# CY8C5888LTI_LP097 register map
File version: 0.1
CY8C58LP
Registers are 8-bit, read-write, no defined reset value unless marked. A register's access mark holds for its fields unless they carry their own. Offsets are from the block's base; lines under a group give offsets from that group; [hi:lo] are bit positions; {n}, {i} and the like mark numbered series; 'fields as' and 'values as' point back to an identical list; <NAME> marks a mode.

## Memory map
0x00000000 PWM_PERISTALTISK_1
0x00000000 PWM_PERISTALTISK_2
0x00000000 DS18x8_TimerDelay
0x00000000 DS18x8_ControlReg_SEL
0x00000000 DS18x8_ControlReg_DRV
0x00000000 DS18x8_StatusReg_BUS
0x00000000 DS18x8_Trigger
0x00000000 ADC_PH — SAR ADC

## PWM_PERISTALTISK_1
Base 0x00000000
0x4000642D PWM_PERISTALTISK_1__COMPARE1 — UDB.D0 - Assigned Compare1 Value
0x4000643D PWM_PERISTALTISK_1__COMPARE2 — UDB.D1 - Assigned Compare2 Value
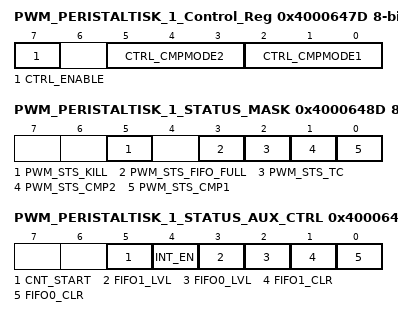
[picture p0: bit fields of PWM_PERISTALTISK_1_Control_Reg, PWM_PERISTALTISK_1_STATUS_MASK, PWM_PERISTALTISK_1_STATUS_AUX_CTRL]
0x4000647D PWM_PERISTALTISK_1_Control_Reg — UDB Control Register - Assigned Control Register Value
  [7] CTRL_ENABLE — Enable the PWM
  [5:3] CTRL_CMPMODE2 — Compare mode 2
  [2:0] CTRL_CMPMODE1 — Compare mode 1
0x4000648D PWM_PERISTALTISK_1_STATUS_MASK — UDB Status bits Interrupt Mask Enable Register
  [5] PWM_STS_KILL ro — Enables the Interrupt on Kill
  [3] PWM_STS_FIFO_FULL ro — FIFO Full Status Mask
  [2] PWM_STS_TC ro — Enables the Interrupt on Terminal Count
  [1] PWM_STS_CMP2 ro — Enables the Interrupt on Compare 2
  [0] PWM_STS_CMP1 ro — Enables the Interrupt on Compare 1
0x4000649D PWM_PERISTALTISK_1_STATUS_AUX_CTRL — UDB Auxilliary Control Register
  [5] CNT_START — FIFO0 clear
    0=E_CNT_START0 (Disable counter); 1=E_CNT_START1 (Enable counter)
  [4] INT_EN
    0=E_INT_EN0 (Interrupt disabled); 1=E_INT_EN1 (Interrupt enabled)
  [3] FIFO1_LVL — FIFO level
    0=E_FIFO_LVL_0 (FIFO LVL: input mode: FIFO not full; output mode: FIFO not empty); 1=E_FIFO_LVL_1 (FIFO LVL: input mode: FIFO at least 1/2 empty; output mode: FIFO at least 1/2 full)
  [2] FIFO0_LVL — FIFO level
    values as FIFO1_LVL
  [1] FIFO1_CLR — FIFO1 clear
    0=E_FIFO_CLR_0 (Normal FIFO operation); 1=E_FIFO_CLR_1 (Clear FIFO state)
  [0] FIFO0_CLR — FIFO0 clear
    values as FIFO1_CLR

## PWM_PERISTALTISK_2
Base 0x00000000
0x40006421 PWM_PERISTALTISK_2_COMPARE_Reg_ — UDB.D0 - Assigned Compare Value
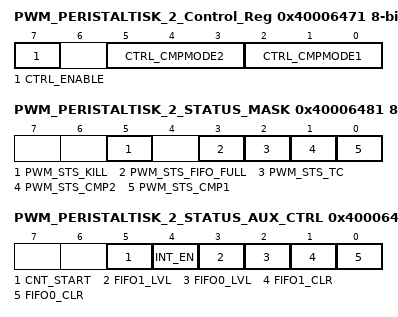
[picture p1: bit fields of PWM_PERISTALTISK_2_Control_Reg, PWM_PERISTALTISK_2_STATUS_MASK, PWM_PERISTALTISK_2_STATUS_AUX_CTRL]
0x40006471 PWM_PERISTALTISK_2_Control_Reg — UDB Control Register - Assigned Control Register Value
  [7] CTRL_ENABLE — Enable the PWM
  [5:3] CTRL_CMPMODE2 — Compare mode 2
  [2:0] CTRL_CMPMODE1 — Compare mode 1
0x40006481 PWM_PERISTALTISK_2_STATUS_MASK — UDB Status bits Interrupt Mask Enable Register
  fields as PWM_PERISTALTISK_1.PWM_PERISTALTISK_1_STATUS_MASK
0x40006491 PWM_PERISTALTISK_2_STATUS_AUX_CTRL — UDB Auxilliary Control Register
  fields as PWM_PERISTALTISK_1.PWM_PERISTALTISK_1_STATUS_AUX_CTRL

## DS18x8_TimerDelay
Base 0x00000000
0x40006402 DS18x8_TimerDelay_COUNTER 16-bit — UDB.A0 - Current Down Counter Value
0x40006422 DS18x8_TimerDelay_PERIOD 16-bit — UDB.D0 - Assigned Period
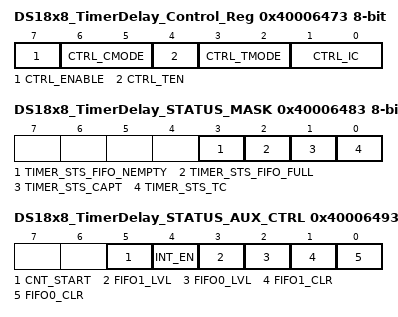
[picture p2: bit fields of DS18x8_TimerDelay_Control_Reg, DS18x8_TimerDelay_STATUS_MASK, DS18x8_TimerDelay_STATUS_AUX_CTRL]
0x40006473 DS18x8_TimerDelay_Control_Reg — UDB Control Register - Assigned Control Register Value
  [7] CTRL_ENABLE — Enable the Timer
  [6:5] CTRL_CMODE — Capture Mode
  [4] CTRL_TEN — Trigger Enable Bit
  [3:2] CTRL_TMODE — Trigger Mode
  [1:0] CTRL_IC — Interrupt Count
0x40006483 DS18x8_TimerDelay_STATUS_MASK — UDB Status bits Interrupt Mask Enable Register
  [3] TIMER_STS_FIFO_NEMPTY ro — FIFO Empty status
  [2] TIMER_STS_FIFO_FULL ro — FIFO Full Status
  [1] TIMER_STS_CAPT ro — Enables the Interrupt on Capture
  [0] TIMER_STS_TC ro — Enables the Interrupt on TC
0x40006493 DS18x8_TimerDelay_STATUS_AUX_CTRL — UDB Auxilliary Control Register
  fields as PWM_PERISTALTISK_1.PWM_PERISTALTISK_1_STATUS_AUX_CTRL

## DS18x8_ControlReg_SEL
Base 0x00000000
0x4000647C DS18x8_ControlReg_SEL_CONTROL_REG

## DS18x8_ControlReg_DRV
Base 0x00000000
0x40006472 DS18x8_ControlReg_DRV_CONTROL_REG

## DS18x8_StatusReg_BUS
Base 0x00000000
0x40006462 DS18x8_StatusReg_BUS_STATUS_REG
0x40006482 DS18x8_StatusReg_BUS_MASK_REG
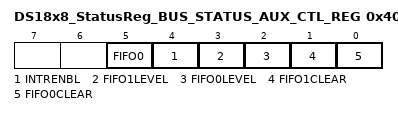
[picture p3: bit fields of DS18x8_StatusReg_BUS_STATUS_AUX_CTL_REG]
0x40006492 DS18x8_StatusReg_BUS_STATUS_AUX_CTL_REG
  [5] FIFO0 — FIFO0 clear
    1=ENABLED (Enable counter); 0=DISABLED (Disable counter)
  [4] INTRENBL — Enables or disables the Interrupt
    1=ENABLED (Interrupt enabled); 0=DISABLED (Interrupt disabled)
  [3] FIFO1LEVEL — FIFO level
    1=ENABLED (FIFO LVL: input mode: FIFO at least 1/2 empty; output mode: FIFO at least 1/2 full); 0=DISABLED (FIFO LVL: input mode: FIFO not full; output mode: FIFO not empty)
  [2] FIFO0LEVEL — FIFO level
    values as FIFO1LEVEL
  [1] FIFO1CLEAR — FIFO clear
    1=ENABLED (Clear FIFO state); 0=DISABLED (Normal FIFO operation)
  [0] FIFO0CLEAR — FIFO clear
    values as FIFO1CLEAR

## DS18x8_Trigger
Base 0x00000000
0x40006470 DS18x8_Trigger_CONTROL_REG

## ADC_PH — SAR ADC
Base 0x00000000
0x40004614 SAR_TR0 — SAR trim register
{0x40005900+i} SAR_CSR{i} (i=0..6) — SAR status and control register {i}
0x40005B20 SAR_SW0 — SAR Analog Routing Register 0
{0x40005B20+i} SAR_SW{i} (i=2..4) — SAR Analog Routing Register {i}
0x40005B26 SAR_SW6 — SAR Analog Routing Register 6
0x40005B27 SAR_CLK — SAR Clock Selection Register
0x40005BA0 SAR_WRK 16-bit — SAR working register
